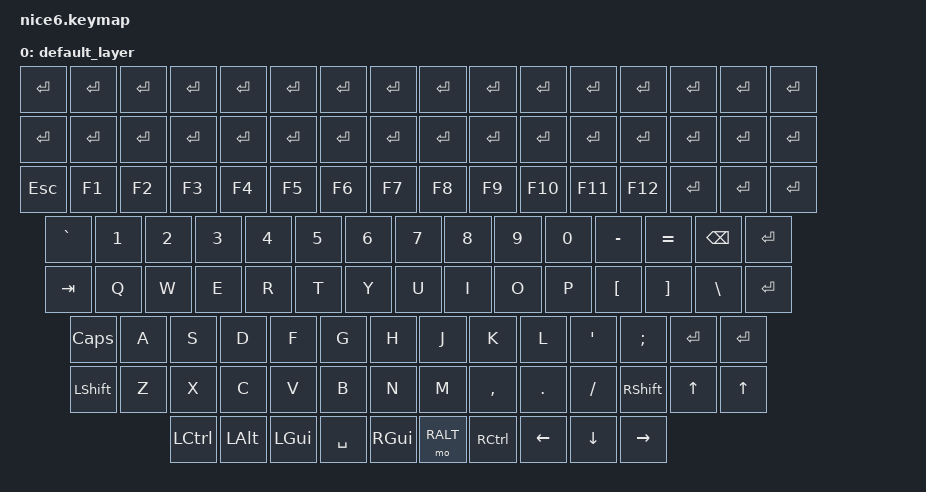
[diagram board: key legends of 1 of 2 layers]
/*
 * Copyright (c) 2021 Nick Winans
 *
 * SPDX-License-Identifier: MIT
 */

#include <behaviors.dtsi>
#include <dt-bindings/zmk/keys.h>
#include <dt-bindings/zmk/rgb.h>
#include <dt-bindings/zmk/bt.h>

/ {
    keymap {
        compatible = "zmk,keymap";

        default_layer {
            bindings = <
                &kp ENTER     &kp ENTER      &kp ENTER      &kp ENTER      &kp ENTER      &kp ENTER      &kp ENTER      &kp ENTER      &kp ENTER      &kp ENTER     &kp ENTER     &kp ENTER      &kp ENTER   &kp ENTER     &kp ENTER   &kp ENTER

                &kp ENTER     &kp ENTER      &kp ENTER      &kp ENTER      &kp ENTER      &kp ENTER      &kp ENTER      &kp ENTER      &kp ENTER      &kp ENTER     &kp ENTER     &kp ENTER      &kp ENTER   &kp ENTER     &kp ENTER   &kp ENTER
                
                &kp ESC     &kp F1      &kp F2      &kp F3      &kp F4      &kp F5      &kp F6      &kp F7      &kp F8      &kp F9     &kp F10     &kp F11      &kp F12   &kp ENTER     &kp ENTER   &kp ENTER
                
                &kp GRAVE   &kp 1       &kp 2       &kp 3       &kp 4       &kp 5       &kp 6       &kp 7       &kp 8       &kp 9      &kp 0       &kp MINUS    &kp EQUAL   &kp BSPC    &kp ENTER
                
                &kp TAB     &kp Q       &kp W       &kp E       &kp R       &kp T       &kp Y       &kp U       &kp I       &kp O      &kp P       &kp LBKT     &kp RBKT    &kp BSLH    &kp ENTER
                
                &kp CAPS    &kp A       &kp S       &kp D       &kp F       &kp G       &kp H       &kp J       &kp K       &kp L      &kp SQT     &kp SEMI     &kp ENTER   &kp ENTER
                
                &kp LSHFT   &kp Z       &kp X       &kp C       &kp V       &kp B       &kp N       &kp M       &kp COMMA   &kp DOT    &kp SLASH   &kp RSHFT    &kp UP      &kp UP
                
                &kp LCTRL   &kp LALT    &kp LGUI    &kp SPACE   &kp RGUI   &mo RALT     &kp RCTRL    &kp LEFT    &kp DOWN    &kp RIGHT
            >;
        };

        rgb_layer {
// ------------------------------------------------------------------------------------------------
// | BT CLR | F1  | F2  | F3  | F4  | F5  | F6  | F7  | F8  | F9  | F10  | F11 | F12 | EFFECT REV |
// |  BT 1   |   |  UP |   | HUEUP | SATUP | BRIUP | SPDUP |   |     |    |     |     |           |
// |   BT 2   | LT |  DN  | RT | HUEDN | SATDN | BRIDN | SPDDN |   |     |   |     |  EFFECT FORW |
// |    BT 3     |     |      |      |     |     |     |     |     |     |     |                  |
// |   BT 4  |      |      |             TOG RGB                | PRT SCR |       |       |  DEL  |
// ------------------------------------------------------------------------------------------------
            bindings = <
    &bt BT_CLR   &kp F1    &kp F2    &kp F3  &kp F4           &kp F5          &kp F6          &kp F7          &kp F8   &kp F9   &kp F10  &kp F11 &kp F12  &rgb_ug RGB_EFR
    &bt BT_SEL 0  &trans    &kp UP    &trans  &rgb_ug RGB_HUI  &rgb_ug RGB_SAI &rgb_ug RGB_BRI &rgb_ug RGB_SPI  &trans   &trans   &trans   &trans  &trans          &trans
    &bt BT_SEL 1   &kp LEFT  &kp DOWN  &kp RIGHT &rgb_ug RGB_HUD &rgb_ug RGB_SAD &rgb_ug RGB_BRD &rgb_ug RGB_SPD &trans   &trans   &trans   &trans        &rgb_ug RGB_EFF
    &bt BT_SEL 2    &trans    &trans    &trans   &trans          &trans          &trans          &trans          &trans   &trans   &trans                          &trans
    &bt BT_SEL 3  &trans   &trans                            &rgb_ug RGB_TOG                                      &kp PSCRN      &trans      &trans               &kp DEL
            >;
        };
    };
};
